# CY8C5588AXI_060ES1 register map
File version: 0.1
CY8C55
Registers are 8-bit, read-write, no defined reset value unless marked. A register's access mark holds for its fields unless they carry their own. Offsets are from the block's base; lines under a group give offsets from that group; [hi:lo] are bit positions; {n}, {i} and the like mark numbered series; 'fields as' and 'values as' point back to an identical list; <NAME> marks a mode.

## Memory map
0x400043A3 TimerServoSharp size 0xB62
0x400043AA ADCSharp size 0x17E0
0x40006426 UART_Asser size 0x41 — UART
0x40006443 UART_XBee size 0x105 — UART
0x40006487 Timer_Fin size 0xEE

## TimerServoSharp
Base 0x400043A3
0x00 TimerServoSharp_GLOBAL_ENABLE — PM.ACT.CFG
  [3:0] en_timer — Enable timer/counters.
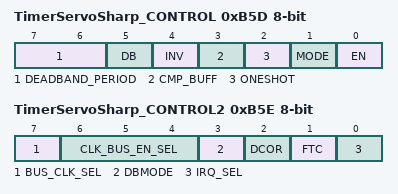
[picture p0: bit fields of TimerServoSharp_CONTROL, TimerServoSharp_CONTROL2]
0xB5D TimerServoSharp_CONTROL — TMRx.CFG0
  [7:6] DEADBAND_PERIOD
  [5] DB — Deadband mode--Deadband phases phi1 and phi2 are outputted on CMP and TC output pins respectively.
    0=Timer (CMP and TC are output.); 1=Deadband (PHI1 (instead of CMP) and PHI2 (instead of TC) are output.)
  [4] INV — Invert sense of TIMEREN signal
  [3] CMP_BUFF — Buffer compare register. Compare register updates only on timer terminal count.
  [2] ONESHOT — Timer stops upon reaching stop condition defined by TMR_CFG bits. Can be restarted by asserting TIMER RESET or disabling and re-enabling block.
  [1] MODE — Mode. (0 = Timer; 1 = Comparator)
    0=Timer mode. CNT/CMP register holds timer count value.; 1=Comparator mode. CNT/CMP register holds comparator threshold value.
  [0] EN — Enables timer/comparator.
0xB5E TimerServoSharp_CONTROL2 — TMRx.CFG1
  [7] BUS_CLK_SEL — Bus Clock selection.
  [6:4] CLK_BUS_EN_SEL — Digital Global Clock selection.
  [3] DBMODE — Deadband mode (asynchronous/synchronous). CMP output pin is also affected when not in deadband mode (CFG0.DEADBAND).
  [2] DCOR — Disable Clear on Read (DCOR) of Status Register SR0.
  [1] FTC — First Terminal Count (FTC). Setting this bit forces a single pulse on the TC pin when first enabled.
    0=Disable_FTC (Disable the single cycle pulse, which signifies the timer is starting.); 1=Enable_FTC (Enable the single cycle pulse, which signifies the timer is starting.)
  [0] IRQ_SEL — Irq selection. (0 = raw interrupts; 1 = status register interrupts)
0xB5F TimerServoSharp_PERIOD — TMRx.PER0 - Assigned Period
0xB61 TimerServoSharp_COUNTER — TMRx.CNT_CMP0 - Current Down Counter Value

## UART_Asser — UART
Base 0x40006426
0x00 RX_UART_Asser_RX_ADDRESS1 — RX Address1 Register
0x10 RX_UART_Asser_RX_ADDRESS2 — RX Address2 Register
0x1B TX_UART_Asser_TX_DATA — TX Data Register
0x20 RX_UART_Asser_RX_DATA — RX Data Register
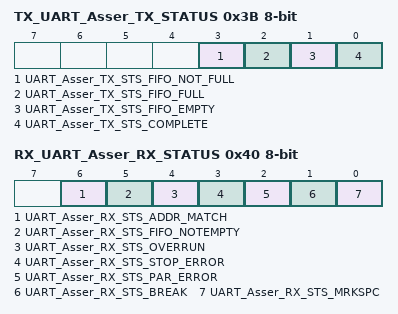
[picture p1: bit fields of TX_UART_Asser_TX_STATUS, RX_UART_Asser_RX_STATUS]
0x3B TX_UART_Asser_TX_STATUS — TX status register
  [3] UART_Asser_TX_STS_FIFO_NOT_FULL ro, [2] UART_Asser_TX_STS_FIFO_FULL ro, [1] UART_Asser_TX_STS_FIFO_EMPTY ro, [0] UART_Asser_TX_STS_COMPLETE ro
0x40 RX_UART_Asser_RX_STATUS — RX status register
  [6] UART_Asser_RX_STS_ADDR_MATCH ro, [5] UART_Asser_RX_STS_FIFO_NOTEMPTY ro, [4] UART_Asser_RX_STS_OVERRUN ro, [3] UART_Asser_RX_STS_STOP_ERROR ro, [2] UART_Asser_RX_STS_PAR_ERROR ro, [1] UART_Asser_RX_STS_BREAK ro, [0] UART_Asser_RX_STS_MRKSPC ro

## UART_XBee — UART
Base 0x40006443
0x00 TX_UART_XBee_TX_DATA — TX Data Register
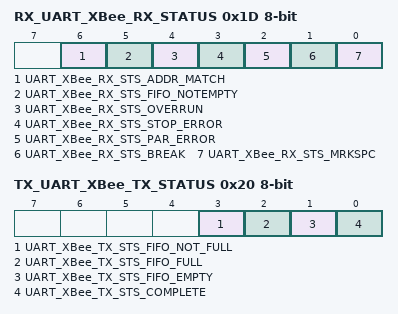
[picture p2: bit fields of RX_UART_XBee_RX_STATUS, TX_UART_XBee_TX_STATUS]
0x1D RX_UART_XBee_RX_STATUS — RX status register
  [6] UART_XBee_RX_STS_ADDR_MATCH ro, [5] UART_XBee_RX_STS_FIFO_NOTEMPTY ro, [4] UART_XBee_RX_STS_OVERRUN ro, [3] UART_XBee_RX_STS_STOP_ERROR ro, [2] UART_XBee_RX_STS_PAR_ERROR ro, [1] UART_XBee_RX_STS_BREAK ro, [0] UART_XBee_RX_STS_MRKSPC ro
0x20 TX_UART_XBee_TX_STATUS — TX status register
  [3] UART_XBee_TX_STS_FIFO_NOT_FULL ro, [2] UART_XBee_TX_STS_FIFO_FULL ro, [1] UART_XBee_TX_STS_FIFO_EMPTY ro, [0] UART_XBee_TX_STS_COMPLETE ro
0xE4 RX_UART_XBee_RX_ADDRESS1 — RX Address1 Register
0xF4 RX_UART_XBee_RX_ADDRESS2 — RX Address2 Register
0x104 RX_UART_XBee_RX_DATA — RX Data Register

## Timer_Fin
Base 0x40006487
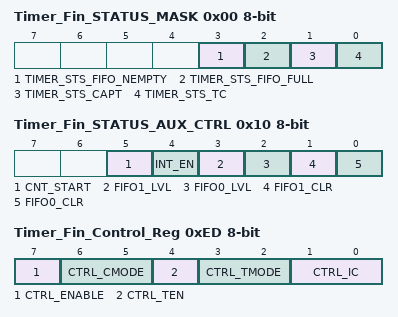
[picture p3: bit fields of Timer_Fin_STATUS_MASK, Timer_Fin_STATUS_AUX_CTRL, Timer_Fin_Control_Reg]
0x00 Timer_Fin_STATUS_MASK — UDB Status bits Interrupt Mask Enable Register
  [3] TIMER_STS_FIFO_NEMPTY ro — FIFO Empty status
  [2] TIMER_STS_FIFO_FULL ro — FIFO Full Status
  [1] TIMER_STS_CAPT ro — Enables the Interrupt on Capture
  [0] TIMER_STS_TC ro — Enables the Interrupt on TC
0x10 Timer_Fin_STATUS_AUX_CTRL — UDB Auxilliary Control Register
  [5] CNT_START — FIFO0 clear
    0=E_CNT_START0 (Disable counter); 1=E_CNT_START1 (Enable counter)
  [4] INT_EN
    0=E_INT_EN0 (Interrupt disabled); 1=E_INT_EN1 (Interrupt enabled)
  [3] FIFO1_LVL — FIFO level
    0=E_FIFO_LVL_0 (FIFO LVL: input mode: FIFO not full; output mode: FIFO not empty); 1=E_FIFO_LVL_1 (FIFO LVL: input mode: FIFO at least 1/2 empty; output mode: FIFO at least 1/2 full)
  [2] FIFO0_LVL — FIFO level
    values as FIFO1_LVL
  [1] FIFO1_CLR — FIFO1 clear
    0=E_FIFO_CLR_0 (Normal FIFO operation); 1=E_FIFO_CLR_1 (Clear FIFO state)
  [0] FIFO0_CLR — FIFO0 clear
    values as FIFO1_CLR
0x7D Timer_Fin_COUNTER 24-bit — UDB.A0 - Current Down Counter Value
0x9D Timer_Fin_PERIOD 24-bit — UDB.D0 - Assigned Period
0xED Timer_Fin_Control_Reg — UDB Control Register - Assigned Control Register Value
  [7] CTRL_ENABLE — Enable the Timer
  [6:5] CTRL_CMODE — Capture Mode
  [4] CTRL_TEN — Trigger Enable Bit
  [3:2] CTRL_TMODE — Trigger Mode
  [1:0] CTRL_IC — Interrupt Count
